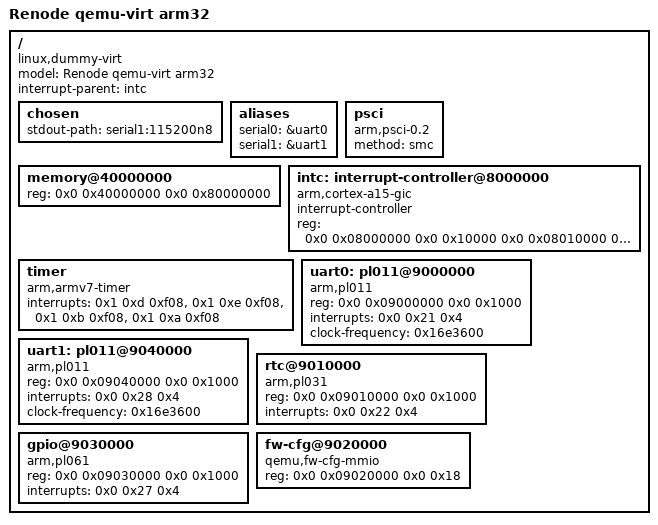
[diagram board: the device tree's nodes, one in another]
/dts-v1/;

/ {
    #address-cells = <0x2>;
    #size-cells = <0x2>;
    compatible = "linux,dummy-virt";
    model = "Renode qemu-virt arm32";
    interrupt-parent = <&intc>;

    chosen {
        stdout-path = "serial1:115200n8";
    };

    aliases {
        serial0 = &uart0;
        serial1 = &uart1;
    };

    psci {
        compatible = "arm,psci-0.2";
        method = "smc";
    };

    memory@40000000 {
        device_type = "memory";
        reg = <0x0 0x40000000 0x0 0x80000000>;
    };

    intc: interrupt-controller@8000000 {
        compatible = "arm,cortex-a15-gic";
        #interrupt-cells = <0x3>;
        interrupt-controller;
        reg = <0x0 0x08000000 0x0 0x10000
               0x0 0x08010000 0x0 0x10000>;
    };

    timer {
        compatible = "arm,armv7-timer";
        interrupts = <0x1 0xd 0xf08>,
                     <0x1 0xe 0xf08>,
                     <0x1 0xb 0xf08>,
                     <0x1 0xa 0xf08>;
    };

    uart0: pl011@9000000 {
        compatible = "arm,pl011", "arm,primecell";
        reg = <0x0 0x09000000 0x0 0x1000>;
        interrupts = <0x0 0x21 0x4>;
        clock-frequency = <0x16e3600>;
    };

    uart1: pl011@9040000 {
        compatible = "arm,pl011", "arm,primecell";
        reg = <0x0 0x09040000 0x0 0x1000>;
        interrupts = <0x0 0x28 0x4>;
        clock-frequency = <0x16e3600>;
    };

    rtc@9010000 {
        compatible = "arm,pl031", "arm,primecell";
        reg = <0x0 0x09010000 0x0 0x1000>;
        interrupts = <0x0 0x22 0x4>;
    };

    gpio@9030000 {
        compatible = "arm,pl061", "arm,primecell";
        reg = <0x0 0x09030000 0x0 0x1000>;
        interrupts = <0x0 0x27 0x4>;
    };

    fw-cfg@9020000 {
        compatible = "qemu,fw-cfg-mmio";
        reg = <0x0 0x09020000 0x0 0x18>;
    };
};
